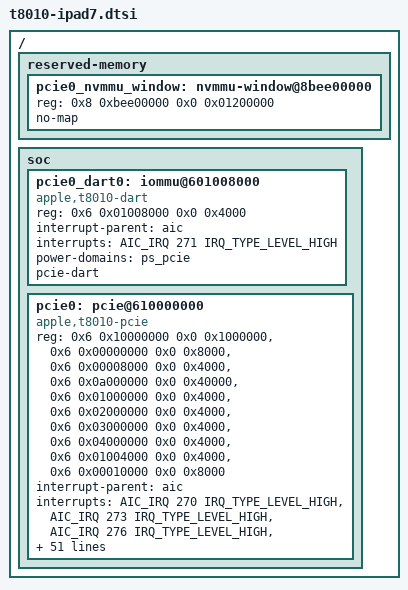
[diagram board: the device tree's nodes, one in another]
// SPDX-License-Identifier: GPL-2.0+ OR MIT
/*
 * Apple iPad 7 common device tree
 *
 * Copyright (c) 2022, Konrad Dybcio <konradybcio@kernel.org>
 */

/*
 * The iPad 7 seems to be only an iteration over the iPad 6 with some
 * small changes, like the a bigger screen and 1 GiB of RAM more, hence
 * there is little to no differentiation between these 2 generations for
 * now.
 */
#include "t8010-ipad6.dtsi"

/ {
	reserved-memory {
		#address-cells = <2>;
		#size-cells = <2>;
		ranges;

		pcie0_nvmmu_window: nvmmu-window@8bee00000 {
			reg = <0x8 0xbee00000 0x0 0x01200000>;
			no-map;
		};
	};

	soc {
		pcie0_dart0: iommu@601008000 {
			compatible = "apple,t8010-dart";
			reg = <0x6 0x01008000 0x0 0x4000>;
			#iommu-cells = <1>;
			interrupt-parent = <&aic>;
			interrupts = <AIC_IRQ 271 IRQ_TYPE_LEVEL_HIGH>;
			power-domains = <&ps_pcie>;
			pcie-dart;
		};

		pcie0: pcie@610000000 {
			compatible = "apple,t8010-pcie";
			device_type = "pci";
			status = "okay";

			reg = <0x6 0x10000000 0x0 0x1000000>,
			      <0x6 0x00000000 0x0 0x8000>,
			      <0x6 0x00008000 0x0 0x4000>,
			      <0x6 0x0a000000 0x0 0x40000>,
			      <0x6 0x01000000 0x0 0x4000>,
			      <0x6 0x02000000 0x0 0x4000>,
			      <0x6 0x03000000 0x0 0x4000>,
			      <0x6 0x04000000 0x0 0x4000>,
			      <0x6 0x01004000 0x0 0x4000>,
			      <0x6 0x00010000 0x0 0x8000>;
			reg-names = "config", "phy0", "phy1", "phy2",
				    "port0", "port1", "port2", "port3",
				    "nvmmu0", "pcieclk-postup";

			interrupt-parent = <&aic>;
			interrupts = <AIC_IRQ 270 IRQ_TYPE_LEVEL_HIGH>,
				     <AIC_IRQ 273 IRQ_TYPE_LEVEL_HIGH>,
				     <AIC_IRQ 276 IRQ_TYPE_LEVEL_HIGH>,
				     <AIC_IRQ 279 IRQ_TYPE_LEVEL_HIGH>,
				     <AIC_IRQ 288 IRQ_TYPE_EDGE_RISING>,
				     <AIC_IRQ 289 IRQ_TYPE_EDGE_RISING>,
				     <AIC_IRQ 290 IRQ_TYPE_EDGE_RISING>,
				     <AIC_IRQ 291 IRQ_TYPE_EDGE_RISING>,
				     <AIC_IRQ 292 IRQ_TYPE_EDGE_RISING>,
				     <AIC_IRQ 293 IRQ_TYPE_EDGE_RISING>,
				     <AIC_IRQ 294 IRQ_TYPE_EDGE_RISING>,
				     <AIC_IRQ 295 IRQ_TYPE_EDGE_RISING>,
				     <AIC_IRQ 296 IRQ_TYPE_EDGE_RISING>,
				     <AIC_IRQ 297 IRQ_TYPE_EDGE_RISING>,
				     <AIC_IRQ 298 IRQ_TYPE_EDGE_RISING>,
				     <AIC_IRQ 299 IRQ_TYPE_EDGE_RISING>,
				     <AIC_IRQ 300 IRQ_TYPE_EDGE_RISING>,
				     <AIC_IRQ 301 IRQ_TYPE_EDGE_RISING>,
				     <AIC_IRQ 302 IRQ_TYPE_EDGE_RISING>,
				     <AIC_IRQ 303 IRQ_TYPE_EDGE_RISING>,
				     <AIC_IRQ 304 IRQ_TYPE_EDGE_RISING>,
				     <AIC_IRQ 305 IRQ_TYPE_EDGE_RISING>,
				     <AIC_IRQ 306 IRQ_TYPE_EDGE_RISING>,
				     <AIC_IRQ 307 IRQ_TYPE_EDGE_RISING>,
				     <AIC_IRQ 308 IRQ_TYPE_EDGE_RISING>,
				     <AIC_IRQ 309 IRQ_TYPE_EDGE_RISING>,
				     <AIC_IRQ 310 IRQ_TYPE_EDGE_RISING>,
				     <AIC_IRQ 311 IRQ_TYPE_EDGE_RISING>,
				     <AIC_IRQ 312 IRQ_TYPE_EDGE_RISING>,
				     <AIC_IRQ 313 IRQ_TYPE_EDGE_RISING>,
				     <AIC_IRQ 314 IRQ_TYPE_EDGE_RISING>,
				     <AIC_IRQ 315 IRQ_TYPE_EDGE_RISING>,
				     <AIC_IRQ 316 IRQ_TYPE_EDGE_RISING>,
				     <AIC_IRQ 317 IRQ_TYPE_EDGE_RISING>,
				     <AIC_IRQ 318 IRQ_TYPE_EDGE_RISING>,
				     <AIC_IRQ 319 IRQ_TYPE_EDGE_RISING>,
				     <AIC_IRQ 272 IRQ_TYPE_EDGE_RISING>;

			msi-controller;
			msi-parent = <&pcie0>;
			apple,msi-doorbell = <0xbffff000>;
			apple,enabled-ports = <0x1>;
			apple,nvmmu-iova = <0xbc000000>;
			memory-region = <&pcie0_nvmmu_window>;

			iommu-map = <0x100 &pcie0_dart0 0 1>;
			iommu-map-mask = <0xff00>;

			#address-cells = <3>;
			#size-cells = <2>;
			#interrupt-cells = <1>;
			interrupt-controller;
			bus-range = <0x00 0x0f>;
			ranges = <0x03000000 0x0 0xc0000000
				  0x7 0xc0000000 0x0 0x40000000>;

			clocks = <&clkref>, <&clkref>, <&clkref>;
			clock-names = "core", "aux", "ref";
			power-domains = <&ps_pcie>, <&ps_pcie_aux>,
					<&ps_pcie_ref>;
			power-domain-names = "core", "aux", "ref";

			reset-gpios = <&pinctrl_ap 12 GPIO_ACTIVE_HIGH>,
				      <&pinctrl_ap 13 GPIO_ACTIVE_HIGH>,
				      <&pinctrl_ap 14 GPIO_ACTIVE_HIGH>,
				      <&pinctrl_ap 15 GPIO_ACTIVE_HIGH>;
			clkreq-gpios = <&pinctrl_ap 16 GPIO_ACTIVE_HIGH>,
				       <&pinctrl_ap 17 GPIO_ACTIVE_HIGH>,
				       <&pinctrl_ap 18 GPIO_ACTIVE_HIGH>,
				       <&pinctrl_ap 19 GPIO_ACTIVE_HIGH>;
		};
	};
};
